# TMS320F280049 register map
Vendor: Texas Instruments; Series: C2000 F28004x; File version: 0.2.0-generated
Registers are 16-bit, read-write, reset 0x0 unless marked. A register's access mark holds for its fields unless they carry their own. Offsets are from the block's base; [hi:lo] are bit positions.

## SPIAREGS — SPI Registers
Base 0x0000C200
Same registers: SPIBREGS 0x0000C220
0x00 SPICCR — SPI Configuration Control Register
  [7] SPISWRESET — SPI Software Reset
  [6] CLKPOLARITY — Shift Clock Polarity
  [5] HS_MODE — High Speed mode control
  [4] SPILBK — SPI Loopback
  [6:3] SPICHAR — Character Length Control
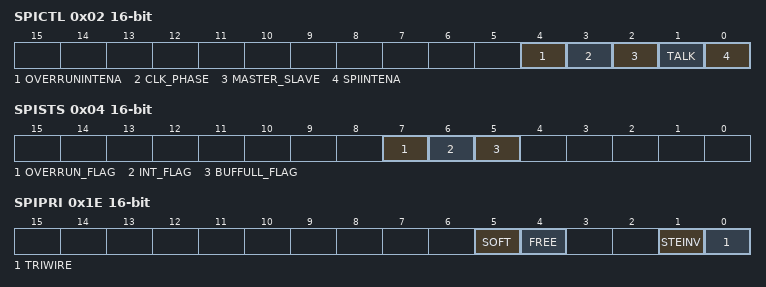
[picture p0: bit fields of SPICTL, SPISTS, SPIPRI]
0x02 SPICTL — SPI Operation Control Register
  [4] OVERRUNINTENA — Overrun Interrupt Enable
  [3] CLK_PHASE — SPI Clock Phase
  [2] MASTER_SLAVE — SPI Network Mode Control
  [1] TALK — Master/Slave Transmit Enable
  [0] SPIINTENA — SPI Interupt Enable
0x04 SPISTS — SPI Status Register
  [7] OVERRUN_FLAG — SPI Receiver Overrun Flag
  [6] INT_FLAG — SPI Interrupt Flag
  [5] BUFFULL_FLAG — SPI Transmit Buffer Full Flag
0x08 SPIBRR — SPI Baud Rate Register
  [12:6] SPI_BIT_RATE — SPI Bit Rate Control
0x0C SPIRXEMU — SPI Emulation Buffer Register
  [15] ERXBN — Emulation Buffer Received Data
0x0E SPIRXBUF — SPI Serial Input Buffer Register
  [15] RXBN — Received Data
0x10 SPITXBUF — SPI Serial Output Buffer Register
  [15] TXBN — Transmit Data Buffer
0x12 SPIDAT — SPI Serial Data Register
  [15] SDATN — Serial Data Shift Register
0x14 SPIFFTX — SPI FIFO Transmit Register
  [15] SPIRST — SPI Reset
  [14] SPIFFENA — FIFO Enhancements Enable
  [13] TXFIFO — TXFIFO Reset
  [15:12] TXFFST — Transmit FIFO Status
  [7] TXFFINT — TXFIFO Interrupt Flag
  [6] TXFFINTCLR — TXFIFO Interrupt Clear
  [5] TXFFIENA — TXFIFO Interrupt Enable
  [8:4] TXFFIL — TXFIFO Interrupt Level
0x16 SPIFFRX — SPI FIFO Receive Register
  [15] RXFFOVF — Receive FIFO Overflow Flag
  [14] RXFFOVFCLR — Receive FIFO Overflow Clear
  [13] RXFIFORESET
  [15:12] RXFFST — Receive FIFO Status
  [7] RXFFINT — RXFIFO Interrupt Flag
  [6] RXFFINTCLR — RXFIFO Interupt Clear
  [5] RXFFIENA — RXFIFO Interrupt Enable
  [8:4] RXFFIL — RXFIFO Interrupt Level
0x18 SPIFFCT — SPI FIFO Control Register
  [14:7] TXDLY — FIFO Transmit Delay Bits
0x1E SPIPRI — SPI Priority Control Register
  [5] SOFT — Soft emulation mode
  [4] FREE — Free emulation mode
  [1] STEINV — SPISTE inversion bit
  [0] TRIWIRE — 3-wire mode select bit

## CLAPROMCRC32 — CLA PROM CRC32 Registers
Base 0x0000C380
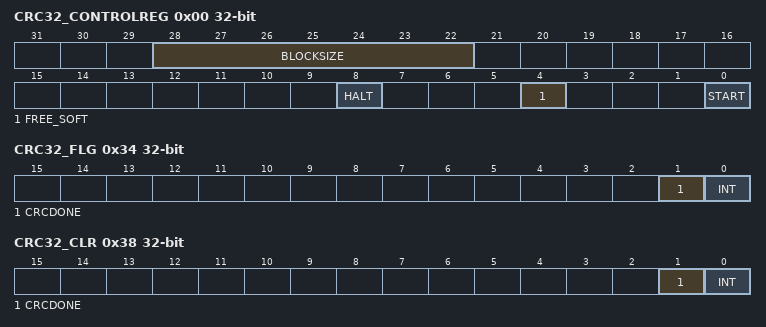
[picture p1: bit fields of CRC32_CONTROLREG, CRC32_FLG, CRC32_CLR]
0x00 CRC32_CONTROLREG 32-bit — CRC32-Control Register
  [28:22] BLOCKSIZE — Block size of ROM for which CRC is to be calculated
  [8] HALT — Halt Bit
  [4] FREE_SOFT — emulation control bit
  [0] START — Start Bit
0x04 CRC32_STARTADDRESS 32-bit
  [31] START_ADDRESS
0x08 CRC32_SEED 32-bit
  [31] SEED — Initial CRC value
0x0C CRC32_STATUSREG 32-bit — CRC32-Status Register
  [31] RUNSTATUS — CRC active status
  [23] CRCCHECKSTATUS — CRC active status
  [30:15] CURRENTADDR — Point to the data fetch unit current address
0x10 CRC32_CRCRESULT 32-bit
  [31] CRCRESULT
0x14 CRC32_GOLDENCRC 32-bit
  [31] GOLDENCRC
0x30 CRC32_INTEN 32-bit — CRC32-Interrupt enable register
  [1] CRCDONE — CRCDONE interrupt enable register
0x34 CRC32_FLG 32-bit — CRC32-Interrupt Flag Register
  [1] CRCDONE — CRCDONE Interrupt status flag
  [0] INT — Global Interrupt status flag
0x38 CRC32_CLR 32-bit — CRC32-Interrupt Clear Register
  [1] CRCDONE — CRCDONE Interrupt clear
  [0] INT — Global Interrupt clear
0x3C CRC32_FRC 32-bit — CRC32-Interrupt Force Register
  [1] CRCDONE — CRCDONE Interrupt force

## WDREGS — WD Registers
Base 0x0000E000
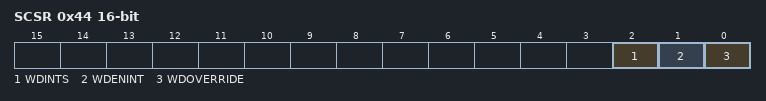
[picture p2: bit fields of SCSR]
0x44 SCSR — System Control and Status Register
  [2] WDINTS — WD Interrupt Status
  [1] WDENINT — WD Interrupt Enable
  [0] WDOVERRIDE — WD Override for WDDIS bit
0x46 WDCNTR — Watchdog Counter Register
  [14:7] WDCNTR — WD Counter
0x4A WDKEY — Watchdog Reset Key Register
  [14:7] WDKEY
0x52 WDCR — Watchdog Control Register
  [14:11] WDPRECLKDIV — WD Pre Clock Divider
  [7] WDFLG — WD Reset Status Flag
  [6] WDDIS — WD Disable
  [7:5] WDCHK — WD Check Bits
  [4:2] WDPS — WD Clock Prescalar
0x54 WDWCR — Watchdog Windowed Control Register
  [8] FIRSTKEY — First Key Detect Flag
  [14:7] MIN — WD Min Threshold setting for Windowed Watchdog functionality
